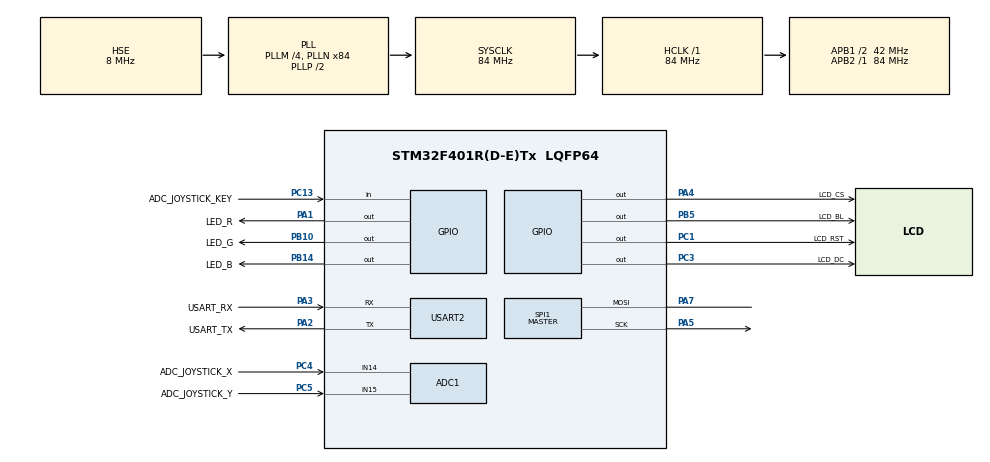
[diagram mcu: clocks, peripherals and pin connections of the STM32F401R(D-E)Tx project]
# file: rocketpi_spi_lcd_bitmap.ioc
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ADC1.Channel-0\#ChannelRegularConversion=ADC_CHANNEL_14
ADC1.Channel-1\#ChannelRegularConversion=ADC_CHANNEL_15
ADC1.ContinuousConvMode=ENABLE
ADC1.EnableAnalogWatchDog=false
ADC1.InjNumberOfConversion=0
ADC1.NbrOfConversion=2
ADC1.NbrOfConversionFlag=1
ADC1.Rank-0\#ChannelRegularConversion=1
ADC1.Rank-1\#ChannelRegularConversion=2
ADC1.SamplingTime-0\#ChannelRegularConversion=ADC_SAMPLETIME_112CYCLES
ADC1.SamplingTime-1\#ChannelRegularConversion=ADC_SAMPLETIME_112CYCLES
ADC1.ScanConvMode=ENABLE
ADC1.master=1
Dma.Request0=SPI1_TX
Dma.SPI1_TX.0.Direction=DMA_MEMORY_TO_PERIPH
Dma.SPI1_TX.0.FIFOMode=DMA_FIFOMODE_DISABLE
Dma.SPI1_TX.0.Instance=DMA2_Stream3
Dma.SPI1_TX.0.MemDataAlignment=DMA_MDATAALIGN_BYTE
Dma.SPI1_TX.0.MemInc=DMA_MINC_ENABLE
Dma.SPI1_TX.0.Mode=DMA_NORMAL
Dma.SPI1_TX.0.PeriphDataAlignment=DMA_PDATAALIGN_BYTE
Dma.SPI1_TX.0.PeriphInc=DMA_PINC_DISABLE
Dma.SPI1_TX.0.Priority=DMA_PRIORITY_LOW
Mcu.Family=STM32F4
Mcu.Name=STM32F401R(D-E)Tx
Mcu.Package=LQFP64
NVIC.DMA2_Stream3_IRQn=true\:0\:0\:false\:false\:true\:false\:true\:true
NVIC.PriorityGroup=NVIC_PRIORITYGROUP_4
NVIC.SPI1_IRQn=true\:0\:0\:false\:false\:true\:true\:true\:true
PA1.GPIO_Label=LED_R
PA1.Signal=GPIO_Output
PA13.GPIO_Label=TMS
PA13.Mode=Serial_Wire
PA13.Signal=SYS_JTMS-SWDIO
PA14.GPIO_Label=TCK
PA14.Mode=Serial_Wire
PA14.Signal=SYS_JTCK-SWCLK
PA2.GPIO_Label=USART_TX
PA2.GPIO_Mode=GPIO_MODE_AF_PP
PA2.GPIO_PuPd=GPIO_NOPULL
PA2.GPIO_Speed=GPIO_SPEED_FREQ_LOW
PA2.Mode=Asynchronous
PA2.Signal=USART2_TX
PA3.GPIO_Label=USART_RX
PA3.GPIO_Mode=GPIO_MODE_AF_PP
PA3.GPIO_PuPd=GPIO_NOPULL
PA3.GPIO_Speed=GPIO_SPEED_FREQ_LOW
PA3.Mode=Asynchronous
PA3.Signal=USART2_RX
PA4.GPIO_Label=LCD_CS
PA4.GPIO_Speed=GPIO_SPEED_FREQ_VERY_HIGH
PA4.PinState=GPIO_PIN_SET
PA4.Signal=GPIO_Output
PA5.Mode=Simplex_Bidirectional_Master
PA5.Signal=SPI1_SCK
PA7.Mode=Simplex_Bidirectional_Master
PA7.Signal=SPI1_MOSI
PB10.GPIO_Label=LED_G
PB10.Signal=GPIO_Output
PB14.GPIO_Label=LED_B
PB14.Signal=GPIO_Output
PB5.GPIO_Label=LCD_BL
PB5.Signal=GPIO_Output
PC1.GPIO_Label=LCD_RST
PC1.Signal=GPIO_Output
PC13-ANTI_TAMP.GPIO_Label=ADC_JOYSTICK_KEY
PC13-ANTI_TAMP.Signal=GPIO_Input
PC3.GPIO_Label=LCD_DC
PC3.Signal=GPIO_Output
PC4.GPIO_Label=ADC_JOYSTICK_X
PC4.Signal=ADCx_IN14
PC5.GPIO_Label=ADC_JOYSTICK_Y
PC5.Signal=ADCx_IN15
PH0\ -\ OSC_IN.Mode=HSE-External-Oscillator
PH0\ -\ OSC_IN.Signal=RCC_OSC_IN
PH1\ -\ OSC_OUT.Mode=HSE-External-Oscillator
PH1\ -\ OSC_OUT.Signal=RCC_OSC_OUT
ProjectManager.HeapSize=0x800
ProjectManager.StackSize=0x800
ProjectManager.TargetToolchain=MDK-ARM V5.27
RCC.48MHZClocksFreq_Value=24000000
RCC.AHBFreq_Value=84000000
RCC.APB1CLKDivider=RCC_HCLK_DIV2
RCC.APB1Freq_Value=42000000
RCC.APB1TimFreq_Value=84000000
RCC.APB2Freq_Value=84000000
RCC.APB2TimFreq_Value=84000000
RCC.CortexFreq_Value=84000000
RCC.HCLKFreq_Value=84000000
RCC.HSE_VALUE=8000000
RCC.HSI_VALUE=16000000
RCC.PLLM=4
RCC.PLLN=84
RCC.PLLQ=7
RCC.PLLSourceVirtual=RCC_PLLSOURCE_HSE
RCC.SYSCLKFreq_VALUE=84000000
RCC.SYSCLKSource=RCC_SYSCLKSOURCE_PLLCLK
RCC.VCOOutputFreq_Value=168000000
SH.ADCx_IN14.0=ADC1_IN14,IN14
SH.ADCx_IN15.0=ADC1_IN15,IN15
SPI1.BaudRatePrescaler=SPI_BAUDRATEPRESCALER_2
SPI1.DataSize=SPI_DATASIZE_8BIT
SPI1.Direction=SPI_DIRECTION_1LINE
SPI1.Mode=SPI_MODE_MASTER
SPI1.VirtualType=VM_MASTER
USART2.VirtualMode=VM_ASYNC
board=NUCLEO-F401RE

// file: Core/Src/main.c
/* USER CODE BEGIN Header */
/**
  ******************************************************************************
  * @file           : main.c
  * @brief          : Main program body
  ******************************************************************************
  * @attention
  *
  * Copyright (c) 2025 STMicroelectronics.
  * All rights reserved.
  *
  * This software is licensed under terms that can be found in the LICENSE file
  * in the root directory of this software component.
  * If no LICENSE file comes with this software, it is provided AS-IS.
  *
  ******************************************************************************
  */
/* USER CODE END Header */
#include "main.h"
#include "adc.h"
#include "dma.h"
#include "spi.h"
#include "usart.h"
#include "gpio.h"

/* USER CODE BEGIN Includes */
#include "st7789.h"
#include "font16x24_ascii.h"
/* USER CODE END Includes */

void SystemClock_Config(void);

int main(void)
{

  /* MCU Configuration--------------------------------------------------------*/

  /* Reset of all peripherals, Initializes the Flash interface and the Systick. */
  HAL_Init();

  /* Configure the system clock */
  SystemClock_Config();

  /* Initialize all configured peripherals */
  MX_GPIO_Init();
  MX_DMA_Init();
  MX_USART2_UART_Init();
  MX_SPI1_Init();
  MX_ADC1_Init();
  /* USER CODE BEGIN 2 */
	extern const unsigned char rgb565_grid_240x240[] ;

  ST7789_Init();
	ST7789_Clear(GRED);

  ST7789_TestFrameRate(); /* 帧率测试 */

  /* USER CODE END 2 */

  /* Infinite loop */
  while (1)
  {

  }
}

void SystemClock_Config(void)
{
  RCC_OscInitTypeDef RCC_OscInitStruct = {0};
  RCC_ClkInitTypeDef RCC_ClkInitStruct = {0};

  /** Configure the main internal regulator output voltage
  */
  __HAL_RCC_PWR_CLK_ENABLE();
  __HAL_PWR_VOLTAGESCALING_CONFIG(PWR_REGULATOR_VOLTAGE_SCALE2);

  /** Initializes the RCC Oscillators according to the specified parameters
  * in the RCC_OscInitTypeDef structure.
  */
  RCC_OscInitStruct.OscillatorType = RCC_OSCILLATORTYPE_HSE;
  RCC_OscInitStruct.HSEState = RCC_HSE_ON;
  RCC_OscInitStruct.PLL.PLLState = RCC_PLL_ON;
  RCC_OscInitStruct.PLL.PLLSource = RCC_PLLSOURCE_HSE;
  RCC_OscInitStruct.PLL.PLLM = 4;
  RCC_OscInitStruct.PLL.PLLN = 84;
  RCC_OscInitStruct.PLL.PLLP = RCC_PLLP_DIV2;
  RCC_OscInitStruct.PLL.PLLQ = 7;
  if (HAL_RCC_OscConfig(&RCC_OscInitStruct) != HAL_OK)
  {
    Error_Handler();
  }

  /** Initializes the CPU, AHB and APB buses clocks
  */
  RCC_ClkInitStruct.ClockType = RCC_CLOCKTYPE_HCLK|RCC_CLOCKTYPE_SYSCLK
                              |RCC_CLOCKTYPE_PCLK1|RCC_CLOCKTYPE_PCLK2;
  RCC_ClkInitStruct.SYSCLKSource = RCC_SYSCLKSOURCE_PLLCLK;
  RCC_ClkInitStruct.AHBCLKDivider = RCC_SYSCLK_DIV1;
  RCC_ClkInitStruct.APB1CLKDivider = RCC_HCLK_DIV2;
  RCC_ClkInitStruct.APB2CLKDivider = RCC_HCLK_DIV1;

  if (HAL_RCC_ClockConfig(&RCC_ClkInitStruct, FLASH_LATENCY_2) != HAL_OK)
  {
    Error_Handler();
  }
}

void Error_Handler(void)
{
  __disable_irq();
  while (1)
  {
  }
}
